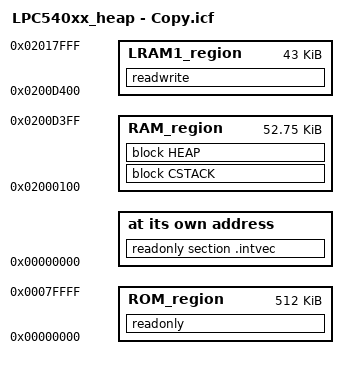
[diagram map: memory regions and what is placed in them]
/*###ICF### Section handled by ICF editor, don't touch! ****/
/*-Editor annotation file-*/
/* IcfEditorFile="$TOOLKIT_DIR$\config\ide\IcfEditor\cortex_v1_0.xml" */
/*-Specials-*/
define symbol __ICFEDIT_intvec_start__ = 0x00000000;
/*-Memory Regions-*/
define symbol __ICFEDIT_region_ROM_start__ = 0x00000000;
define symbol __ICFEDIT_region_ROM_end__   = 0x0007FFFF;
define symbol __ICFEDIT_region_RAM_start__ = 0x02000100;
define symbol __ICFEDIT_region_RAM_end__   = 0x0200D3FF;
/*-Sizes-*/
define symbol __ICFEDIT_size_cstack__ = 0x200;
define symbol __ICFEDIT_size_heap__   = 0xD000;
/**** End of ICF editor section. ###ICF###*/

define symbol __region_LRAM1_start__ = 0x0200D400;
define symbol __region_LRAM1_end__   = 0x02017FFF;

define memory mem with size = 4G;
define region ROM_region   = mem:[from __ICFEDIT_region_ROM_start__   to __ICFEDIT_region_ROM_end__];
define region RAM_region   = mem:[from __ICFEDIT_region_RAM_start__   to __ICFEDIT_region_RAM_end__];
define region LRAM1_region = mem:[from __region_LRAM1_start__         to __region_LRAM1_end__];

define block CSTACK    with alignment = 8, size = __ICFEDIT_size_cstack__   { };
define block HEAP      with alignment = 8, size = __ICFEDIT_size_heap__     { };

initialize by copy { readwrite };
//initialize by copy with packing = none { section __DLIB_PERTHREAD }; // Required in a multi-threaded application
do not initialize  { section .noinit };

place at address mem:__ICFEDIT_intvec_start__ { readonly section .intvec };

place in ROM_region   { readonly };
place in RAM_region   { block CSTACK, block HEAP };
place in LRAM1_region { readwrite };

